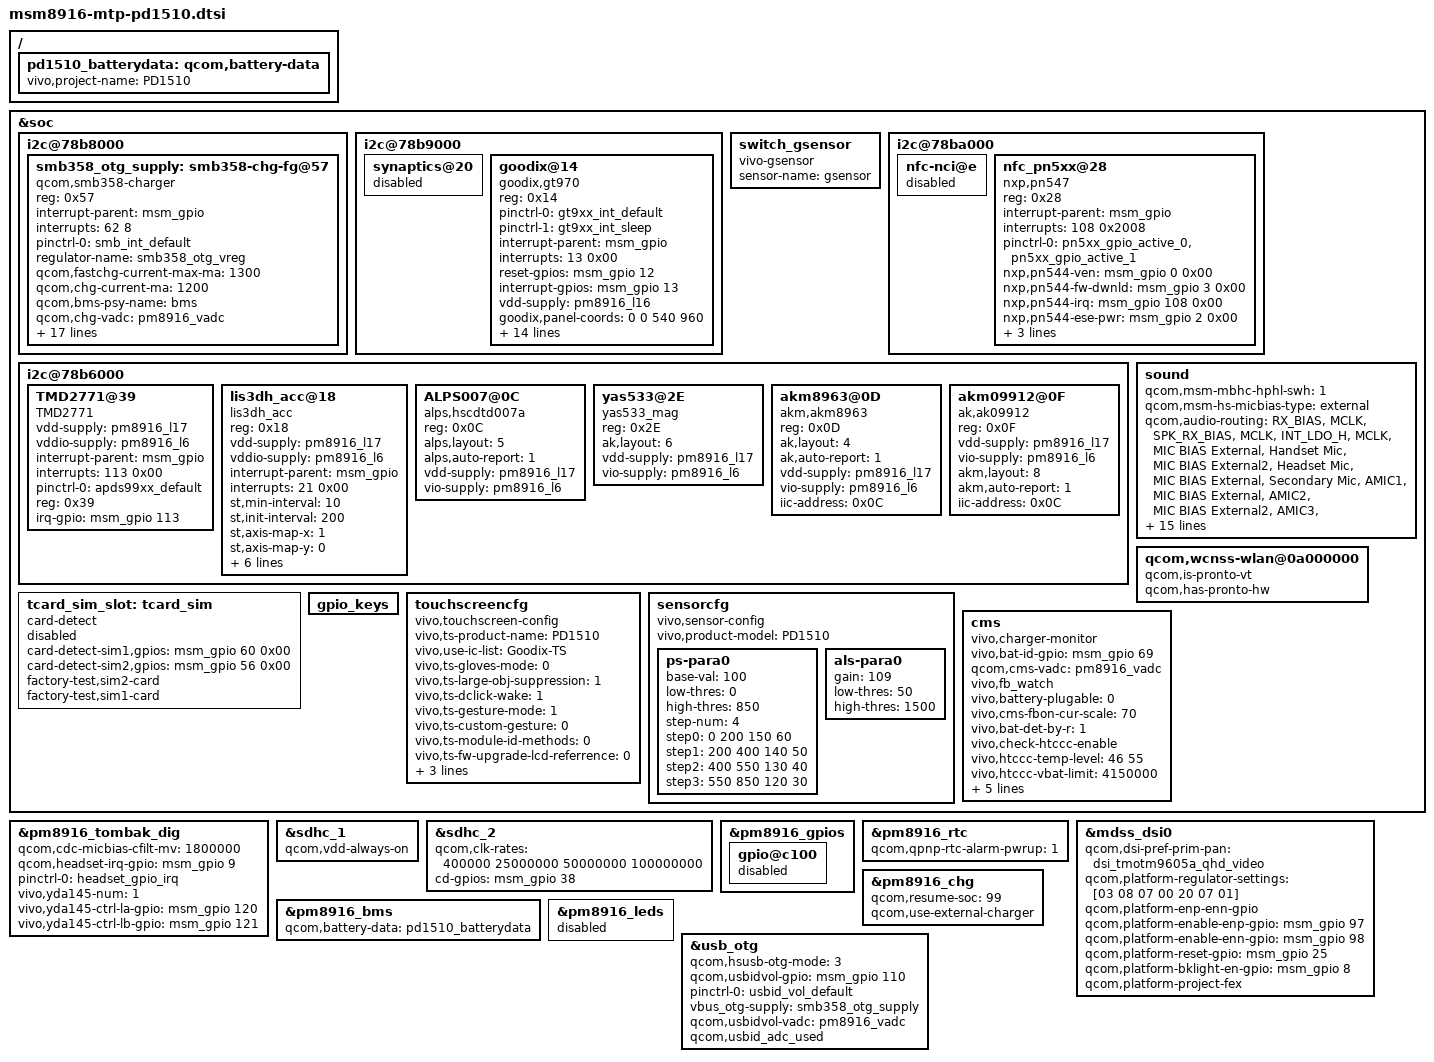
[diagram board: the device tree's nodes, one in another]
/* Copyright (c) 2018, The Linux Foundation. All rights reserved.
*  Copyright (c) 2018, Ketut P. Kumajaya.
*  Copyright (c) 2020, the_shahnawaz_sheikh (sheikhshahnawaz41299).
*
* This program is free software; you can redistribute it and/or modify
* it under the terms of the GNU General Public License version 2 and
* only version 2 as published by the Free Software Foundation.
*
* This program is distributed in the hope that it will be useful,
* but WITHOUT ANY WARRANTY; without even the implied warranty of
* MERCHANTABILITY or FITNESS FOR A PARTICULAR PURPOSE.  See the
* GNU General Public License for more details.
*/

#include "dsi-panel-tmotm9605a-qhd-video.dtsi"
#include "dsi-panel-boeb1otm9605a-qhd-video.dtsi"
#include "dsi-panel-boeotm9605a-qhd-ch-video.dtsi"
#include "dsi-panel-boeotm9605a-qhd-video.dtsi"
#include "dsi-panel-tmotm9605a-qhd-ch-video.dtsi"
#include "dsi-panel-tryhx8389c-qHD-ch-video.dtsi"
#include "dsi-panel-tryhx8389c-qHD-video.dtsi"
#include "dsi-panel-boehx8389c-qHD-video.dtsi"
#include "msm8916-camera-sensor-mtp-pd1510.dtsi"
#include "msm8916-pinctrl-pd1510.dtsi"
#include "msm8916-common-pd1510.dtsi"


&soc {

	i2c@78b8000 {
		smb358_otg_supply: 			smb358-chg-fg@57 {
				compatible = "qcom,smb358-charger";
				reg = <0x57>;
				interrupt-parent = <&msm_gpio>;
				interrupts = <62 8>;
				pinctrl-names = "default";
				pinctrl-0 = <&smb_int_default>;
				regulator-name = "smb358_otg_vreg";
				qcom,fastchg-current-max-ma = <1300>;
				qcom,chg-current-ma = <1200>;
				qcom,bms-psy-name = "bms";
				qcom,chg-vadc = <&pm8916_vadc>;
				qcom,chg-adc_tm = <&pm8916_adc_tm>;
				qcom,hot_bat_decidegc = <550>;
				qcom,cold_bat_decidegc = <(-80)>;
				qcom,bat_present_decidegc = <200>;
				qcom,recharge-mv = <100>;
				qcom,float-voltage-mv = <4360>;
				qcom,iterm-ma = <150>;
				qcom,recharge-disabled = <1>;
				summit,chg-tmout-mins = <600>;
				vcc_i2c-supply = <&pm8916_l5>;
				qcom,chg-input-cur-limit-max = <1000>;
				qcom,chg-fastchg-cur-limit-max = <1300>;
				qcom,fb-on-cur-limit-max = <900>;
				vivo,batt-1C-current-ma = <2350>;
				vivo,charger-enable-soft-term;
				vivo,soft-term-capacity = <99>;
				vivo,soft-term-timer = <120>;//10s,1 per
			};
	};

	

	i2c@78b9000 { /* BLSP1 QUP5 */
		synaptics@20 {
			status = "disabled";
		};
	
		goodix@14 { //gt915L
			compatible = "goodix,gt970";
			reg = <0x14>;
			/* pins used by touchscreen */
			pinctrl-names = "gt9xx_int_default","gt9xx_int_suspend";
            		pinctrl-0 = <&gt9xx_int_default>;
            		pinctrl-1 = <&gt9xx_int_sleep>;
			interrupt-parent = <&msm_gpio>;
			interrupts = <13 0x00>;
			reset-gpios = <&msm_gpio 12 0x00>;
			interrupt-gpios = <&msm_gpio 13 0x00>;
            //vcc_i2c-supply = <&pm8916_l6>;
            vdd-supply = <&pm8916_l16>;/* <&tp_power>;*/
			goodix,panel-coords = <0 0 540 960>;
			goodix,display-coords = <0 0 540 960>;
			goodix,button-map= <158 102 139>;
			goodix,family-id = <0x0>;
            goodix,i2c-pull-up;
			goodix,cfg-data0 =    //Biel
			[
				47 1C 02 07 04 0A 34 10 01 08 
				32 08 4B 32 33 35 00 00 37 13
				00 10 00 14 14 26 14 8C 2C 0D
				46 48 D3 07 D3 07 00 99 33 11
				00 00 00 00 00 00 00 08 0A A0 
				21 28 5F 94 D0 02 3C 1E 00 04
				D0 2B 00 B1 34 1E 9C 3D 00 88
				49 00 78 57 00 78 00 00 00 00 
				00 00 00 00 00 00 00 00 00 00
				00 00 00 00 F7 01 00 00 00 00
				00 00 00 00 00 14 50 00 00 00
				00 1E 1A 18 16 14 12 10 0E 0C
				0A 08 06 04 02 FF 00 00 00 00 
				00 00 00 00 08 00 00 00 DE 00
				00 41 16 18 1C 1D 1E 1F 20 21 
				22 24 26 28 14 13 12 10 0F 0C 
				0A 08 06 04 02 00 FF FF 00 00
				00 00 00 00 00 00 00 00 00 00
				00 00 00 00 1E 01
			];    
			
			goodix,cfg-data2 =    //Truly
			[
				47 1C 02 07 04 0A 34 10 01 08 
				32 08 4B 32 33 35 00 00 37 13
				00 10 00 14 14 26 14 8C 2C 0D
				46 48 D3 07 D3 07 00 99 33 11
				00 00 00 00 00 00 00 08 0A A0 
				21 28 5F 94 D0 02 3C 1E 00 04
				D0 2B 00 B1 34 1E 9C 3D 00 88
				49 00 78 57 00 78 00 00 00 00 
				00 00 00 00 00 00 00 00 00 00
				00 00 00 00 F7 01 00 00 00 00
				00 00 00 00 00 14 50 00 00 00
				00 1E 1A 18 16 14 12 10 0E 0C
				0A 08 06 04 02 FF 00 00 00 00 
				00 00 00 00 08 00 00 00 DE 00
				00 41 16 18 1C 1D 1E 1F 20 21 
				22 24 26 28 14 13 12 10 0F 0C 
				0A 08 06 04 02 00 FF FF 00 00
				00 00 00 00 00 00 00 00 00 00
				00 00 00 00 1E 01
			]; 
			
			goodix,cfg-data3 =    //Yeji
			[
				47 1C 02 07 04 0A 34 10 01 08 
				32 08 4B 32 33 35 00 00 37 13
				00 10 00 14 14 26 14 8C 2C 0D
				46 48 D3 07 D3 07 00 99 33 11
				00 00 00 00 00 00 00 08 0A A0 
				21 28 5F 94 D0 02 3C 1E 00 04
				D0 2B 00 B1 34 1E 9C 3D 00 88
				49 00 78 57 00 78 00 00 00 00 
				00 00 00 00 00 00 00 00 00 00
				00 00 00 00 F7 01 00 00 00 00
				00 00 00 00 00 14 50 00 00 00
				00 1E 1A 18 16 14 12 10 0E 0C
				0A 08 06 04 02 FF 00 00 00 00 
				00 00 00 00 08 00 00 00 DE 00
				00 41 16 18 1C 1D 1E 1F 20 21 
				22 24 26 28 14 13 12 10 0F 0C 
				0A 08 06 04 02 00 FF FF 00 00
				00 00 00 00 00 00 00 00 00 00
				00 00 00 00 1E 01
		      ];                                  
				
			ts-suspend-resume=<0>;
			ts-fixed-key-type=<1>; /*0=0d,1=2d */
			
			/*--virtualkeys: EV_KEY:KEY_MENU:cx:cy:w:h:EV_KEY:KEY_HOMEPAGE:cx:cy:w:h:EV_KEY:KEY_BACK:cx:cy:w:h--*/
			ts-virt-key="0x01:139:90:1028:120:90:0x01:251:181:1028:62:90:0x01:172:272:1028:120:90:0x01:251:368:1028:72:90:0x01:158:464:1028:120:90";
		};
	};
	


         switch_gsensor {
		  compatible = "vivo-gsensor";
		  sensor-name = "gsensor";
		/*  sensor,gpio-irq = <&msm_gpio 21 0x00>;  */
	  };

	i2c@78ba000 { /* BLSP1 QUP6 */
		status = "okay";

		nfc-nci@e {
			status = "disabled";
		};
	};

	i2c@78b6000 { /* BLSP1 QUP2 */
		/delete-node/ mpu6050@68;
		/delete-node/ avago@39;
		/delete-node/ akm@c;

		TMD2771@39 {
			compatible = "TMD2771";
			vdd-supply = <&pm8916_l17>;
			vddio-supply = <&pm8916_l6>;
			interrupt-parent = <&msm_gpio>;
			interrupts = <113 0x00>;
			pinctrl-names = "default";
			pinctrl-0 = <&apds99xx_default>;
			reg = <0x39>;
			irq-gpio = <&msm_gpio 113 0x00>;
		};

		lis3dh_acc@18 {
			compatible = "lis3dh_acc";
			reg = <0x18>;
			vdd-supply = <&pm8916_l17>;
			vddio-supply = <&pm8916_l6>;

			interrupt-parent = <&msm_gpio>;
			interrupts = <21 0x00>;
			st,min-interval = <10>;
			st,init-interval = <200>;
			st,axis-map-x = <1>;
			st,axis-map-y = <0>;
			st,axis-map-z = <2>;
			st,g-range = <2>;
			st,negate-x = <0>;
			st,negate-y = <1>;
			st,negate-z = <0>;
			sensor,gpio-irq = <&msm_gpio 21 0x00>;
		};
		ALPS007@0C {
    		compatible = "alps,hscdtd007a";
    		reg = <0x0C>;
    		alps,layout =<5>;
    		alps,auto-report=<1>;
    		vdd-supply = <&pm8916_l17>;
    		vio-supply = <&pm8916_l6>;
    		};
		yas533@2E {
			compatible = "yas533_mag";
			reg = <0x2E>;
			ak,layout =<6>;
			vdd-supply = <&pm8916_l17>;
			vio-supply = <&pm8916_l6>;

		};
		akm8963@0D {
			compatible = "akm,akm8963";
			reg = <0x0D>;
			ak,layout =<4>;
			ak,auto-report=<1>;
			vdd-supply = <&pm8916_l17>;
			vio-supply = <&pm8916_l6>;
			iic-address=<0x0C>;
		};
		akm09912@0F{
		    compatible = "ak,ak09912";
		    reg = <0x0F>;
		    vdd-supply = <&pm8916_l17>;
		    vio-supply = <&pm8916_l6>;
		    akm,layout = <8>;
		    akm,auto-report=<1>;
		    iic-address=<0x0C>;
	    };

	};
	
	
		/* VIVO_NFC */
	i2c@78ba000 { /* BLSP1 QUP6 */
		status = "okay";
		nfc_pn5xx@28 {
			compatible = "nxp,pn547";
			reg = <0x28>;
			interrupt-parent = <&msm_gpio>;
			interrupts = <108 0x2008>;
			pinctrl-names = "default";
			pinctrl-0 = <&pn5xx_gpio_active_0 &pn5xx_gpio_active_1>;
			nxp,pn544-ven = <&msm_gpio 0 0x00>;
			nxp,pn544-fw-dwnld = <&msm_gpio 3 0x00>;
			nxp,pn544-irq = <&msm_gpio 108 0x00>;
			nxp,pn544-ese-pwr = <&msm_gpio 2 0x00>;
			nxp,pn5xx-clkreq = <&pm8916_gpios 2 0x00>;
			nxp,pn5xx-pvdden_gpio = <&msm_gpio 118 0x00>;
			clock-names = "ref_clk";
			clocks = <&clock_rpm clk_bb_clk2_pin>;
		};
	};
	

	sound {
	/delete-property/	qcom,msm-micbias1-ext-cap;
	/delete-property/	qcom,msm-hs-micbias-type;
		qcom,msm-mbhc-hphl-swh = <1>;
		qcom,msm-hs-micbias-type = "external";
	/delete-property/ qcom,audio-routing;
	qcom,audio-routing =
			"RX_BIAS", "MCLK",
			"SPK_RX_BIAS", "MCLK",
			"INT_LDO_H", "MCLK",
			"MIC BIAS External", "Handset Mic",
			"MIC BIAS External2", "Headset Mic",
			"MIC BIAS External", "Secondary Mic",
			"AMIC1", "MIC BIAS External",
			"AMIC2", "MIC BIAS External2",
			"AMIC3", "MIC BIAS External",
			"DMIC1", "MIC BIAS Internal1",
			"MIC BIAS Internal1", "Digital Mic1",
			"DMIC2", "MIC BIAS Internal1",
			"MIC BIAS Internal1", "Digital Mic2",
			"KTV Handset Mic In", "MIC BIAS External",
			"KTV Headset Mic In", "MIC BIAS External2";
		/delete-property/ pinctrl-names;
			pinctrl-names = "cdc_lines_act",
				"cdc_lines_sus";
		/delete-property/ pinctrl-0;
		/delete-property/ pinctrl-1;
				/delete-property/ pinctrl-2;
		/delete-property/ pinctrl-3;
		/delete-property/ pinctrl-4;
		/delete-property/ pinctrl-5;
			pinctrl-0 = <&cdc_pdm_lines_act>;
			pinctrl-1 = <&cdc_pdm_lines_sus>;
		pinctrl-2 = <&cdc_pdm_lines_act &ext_cdc_tlmm_lines_act>;
		pinctrl-3 = <&cdc_pdm_lines_sus &ext_cdc_tlmm_lines_sus>;

		/delete-property/ qcom,cdc-us-euro-gpios;
				vivo,fm-support;
		vivo,fm-pcm-hp = <5>;
		vivo,fm-pcm-spk = <5>;
	};
	
	
		qcom,wcnss-wlan@0a000000 {
	    /delete-property/ qcom,has-autodetect-xo;
		 qcom,is-pronto-vt;   
		 qcom,has-pronto-hw;  
	};
	
	/delete-node/ gen-vkeys;
	
	tcard_sim_slot:tcard_sim {
		compatible = "card-detect";

		card-detect-sim1,gpios = <&msm_gpio 60 0x00>;
		card-detect-sim2,gpios = <&msm_gpio 56 0x00>;

		factory-test,sim2-card;
		factory-test,sim1-card;
		status = "disabled";
	};

	gpio_keys {
		/delete-node/ camera_focus;
		/delete-node/ camera_snapshot;
	};
};

&pm8916_tombak_dig{
		qcom,cdc-micbias-cfilt-mv = <1800000>;
		qcom,headset-irq-gpio = <&msm_gpio 9 0>;
		pinctrl-names = "headset_gpio_irq";
		pinctrl-0 =  <&headset_gpio_irq>;
		vivo,yda145-num=<1>;
		vivo,yda145-ctrl-la-gpio=<&msm_gpio 120 0>;
		vivo,yda145-ctrl-lb-gpio=<&msm_gpio 121 0>;
};


&sdhc_1 {
	qcom,vdd-always-on;
};

&sdhc_2 {
    /delete-property/ qcom,clk-rates;
	qcom,clk-rates = <400000 25000000 50000000 100000000>;
	cd-gpios = <&msm_gpio 38 0>;
};


&pm8916_gpios {
	gpio@c100 { /* GPIO 2 */
		status = "disabled";
	};
};

&pm8916_rtc {
	qcom,qpnp-rtc-alarm-pwrup = <1>;
};



&mdss_dsi0 {
	qcom,dsi-pref-prim-pan = <&dsi_tmotm9605a_qhd_video>;
        
    /*qcom,dsi-pref-sub-pan = <&dsi_boeb1otm9605a_qhd_vid>;
	qcom,dsi-pref-sub1-pan = <&dsi_boehx8389c_qHD_video>;
    qcom,dsi-pref-sub2-pan = <&dsi_boeotm9605a_qhd_vid_ch>;
    qcom,dsi-pref-sub3-pan = <&dsi_boeotm9605a_qhd_vid>;
    qcom,dsi-pref-sub4-pan = <&dsi_tmotm9605a_qhd_vid_ch>;
    qcom,dsi-pref-sub5-pan = <&dsi_tryhx8389c_qHD_video_ch>;
    qcom,dsi-pref-sub6-pan = <&dsi_tryhx8389c_qHD_video>;*/
    
    qcom,platform-regulator-settings = [03 08 07 00 20 07 01];
	
	/delete-property/ qcom,platform-reset-gpio;
	/delete-property/ qcom,platform-bklight-en-gpio;

	qcom,platform-enp-enn-gpio;
	qcom,platform-enable-enp-gpio = <&msm_gpio 97 0>;
	qcom,platform-enable-enn-gpio = <&msm_gpio 98 0>;
	qcom,platform-reset-gpio = <&msm_gpio 25 0>;
	qcom,platform-bklight-en-gpio = <&msm_gpio 8 0>;
	qcom,platform-project-fex;
};

/ {
	pd1510_batterydata: qcom,battery-data {
         vivo,project-name = "PD1510";	

		/delete-node/ qcom,palladium-batterydata;

		//#include "batterydata-b76-atl-4v35-2260mah.dtsi"
		//#include "batterydata-desay-samsung-2260mah.dtsi"
		//#include "batterydata-atl-ds-4v35-2300mah.dtsi"
		#include "batterydata-samsung-ds-4v35-2300mah.dtsi"
		//#include "batterydata-atl-nvt-4v35-2300mah.dtsi"
	};
};

&pm8916_chg {
	status = "ok";
	qcom,resume-soc = <99>;
	qcom,use-external-charger;
};

&pm8916_bms {
	status = "ok";
	//qcom,resume-soc = <95>;
	qcom,battery-data = <&pd1510_batterydata>;
	//qcom,force-bms-active-on-charger;
    //qcom,use-reported-soc;
};

&pm8916_leds {
	status = "disabled";
};



&soc {
	touchscreencfg { /* vivo ts configure */
	   compatible = "vivo,touchscreen-config";
	   vivo,ts-product-name="PD1510";
	   vivo,use-ic-list="Goodix-TS";
	   
	   /*----- function set BEG ---- */
	   vivo,ts-gloves-mode=<0>;
	   vivo,ts-large-obj-suppression=<1>;
	   vivo,ts-dclick-wake=<1>;
	   vivo,ts-gesture-mode=<1>; /*1=sold in native,2=sold in abroad,3...etc=for custom extensive*/
	   vivo,ts-custom-gesture=<0>;
	   vivo,ts-module-id-methods=<0>;/*0=by IC id,1=gpio,2=by LCD ID 3=...etc=for custom extensive*/
	   vivo,ts-fw-upgrade-lcd-referrence=<0>;
	   vivo,ts-anti-esd=<1>;
	   vivo,ts-charger-conn-judge=<1>;
	   vivo,ts-module-smt-mode=<1>; /* 0=COB,1=COF */
	   /*----- function set END ---- */

	};
	
	sensorcfg {
		compatible = "vivo,sensor-config";
		vivo,product-model = "PD1510";
		ps-para0 {
			base-val = <100>;
			low-thres = <0>;
			high-thres = <850>;
			step-num = <4>;
			step0 = <  0 200 150 60>;
			step1 = <200 400 140 50>;
			step2 = <400 550 130 40>;
			step3 = <550 850 120 30>;
		};
		
		als-para0 {
			gain = <109>;
			low-thres = <50>;
			high-thres = <1500>;
		};
	};
	
	cms {
			compatible = "vivo,charger-monitor";
			vivo,bat-id-gpio = <&msm_gpio 69 0x00>;
			qcom,cms-vadc = <&pm8916_vadc>;
			vivo,fb_watch;
			vivo,battery-plugable = <0>;
			vivo,cms-fbon-cur-scale = <70>;
			vivo,bat-det-by-r = <1>;
			vivo,check-htccc-enable;
			vivo,htccc-temp-level = <46 55>;
			vivo,htccc-vbat-limit = <4150000>;
			vivo,htccc-vbat-delta = <150000>;
			qcom,use-pinctrl;
			pinctrl-names = "default";
			pinctrl-0 = <&batid_default>;
			vivo,chg-current-scale-level = <0 50 70 45 30 30 20 0 0>;
		};
	
};

&usb_otg {
       /delete-property/ qcom,usbid-gpio;
       /delete-property/ pinctrl-names;
       /delete-property/ pinctrl-1;
       /delete-property/ pinctrl-2;
       /delete-property/ qcom,usbin-vadc;
       qcom,hsusb-otg-mode = <3>;
       qcom,usbidvol-gpio = <&msm_gpio 110 0>;
       pinctrl-names = "default";
       pinctrl-0 = <&usbid_vol_default>;
       vbus_otg-supply = <&smb358_otg_supply>;
	   qcom,usbidvol-vadc = <&pm8916_vadc>;
	   qcom,usbid_adc_used;
};
